# MIMXRT1052 register map
Vendor: nxp.com; File version: 1.0
CPU: CM7 r0p1, little endian, MPU, FPU, VTOR, 4 interrupt priority bits
Registers are 32-bit, read-write, reset 0x0 unless marked. A register's access mark holds for its fields unless they carry their own. Offsets are from the block's base; [hi:lo] are bit positions; {n}, {i} and the like mark numbered series; 'fields as' and 'values as' point back to an identical list.

## FLEXIO1 — FLEXIO
Base 0x401AC000
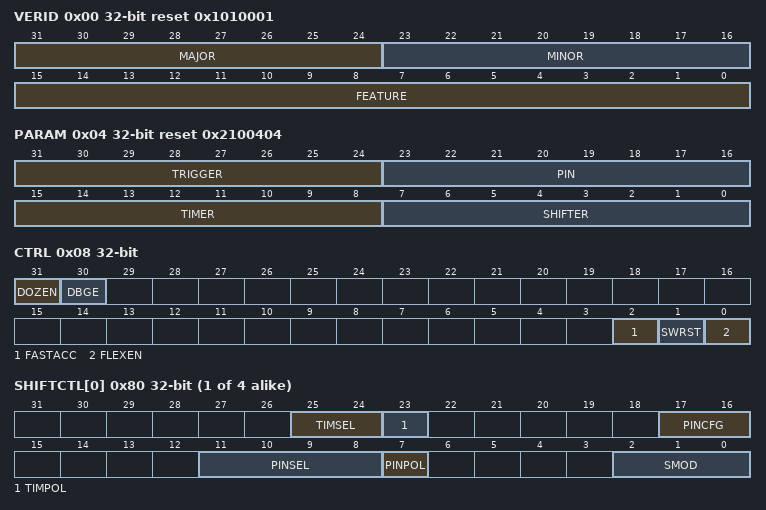
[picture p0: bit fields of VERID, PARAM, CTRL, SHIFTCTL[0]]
0x00 VERID ro reset 0x1010001 — Version ID Register
  [31:24] MAJOR — Major Version Number
  [23:16] MINOR — Minor Version Number
  [15:0] FEATURE — Feature Specification Number
    0=Standard features implemented; 1=Supports state, logic and parallel modes
0x04 PARAM ro reset 0x2100404 — Parameter Register
  [31:24] TRIGGER — Trigger Number
  [23:16] PIN — Pin Number
  [15:8] TIMER — Timer Number
  [7:0] SHIFTER — Shifter Number
0x08 CTRL — FlexIO Control Register
  [31] DOZEN — Doze Enable
    0=FlexIO enabled in Doze modes; 1=FlexIO disabled in Doze modes
  [30] DBGE — Debug Enable
    0=FlexIO is disabled in debug modes; 1=FlexIO is enabled in debug modes
  [2] FASTACC — Fast Access
    0=Configures for normal register accesses to FlexIO; 1=Configures for fast register accesses to FlexIO
  [1] SWRST — Software Reset
    0=Software reset is disabled; 1=Software reset is enabled, all FlexIO registers except the Control Register are reset
  [0] FLEXEN — FlexIO Enable
    0=FlexIO module is disabled; 1=FlexIO module is enabled
0x0C PIN ro — Pin State Register
  [15:0] PDI — Pin Data Input
0x10 SHIFTSTAT — Shifter Status Register
  [3:0] SSF write-1-clears — Shifter Status Flag
0x14 SHIFTERR — Shifter Error Register
  [3:0] SEF write-1-clears — Shifter Error Flags
0x18 TIMSTAT — Timer Status Register
  [3:0] TSF write-1-clears — Timer Status Flags
0x20 SHIFTSIEN — Shifter Status Interrupt Enable
  [3:0] SSIE
0x24 SHIFTEIEN — Shifter Error Interrupt Enable
  [3:0] SEIE
0x28 TIMIEN — Timer Interrupt Enable Register
  [3:0] TEIE — Timer Status Interrupt Enable
0x30 SHIFTSDEN — Shifter Status DMA Enable
  [3:0] SSDE
0x40 SHIFTSTATE — Shifter State Register
  [2:0] STATE — Current State Pointer
{0x80+4i} SHIFTCTL[{i}] (i=0..3) — Shifter Control N Register
  [25:24] TIMSEL — Timer Select
  [23] TIMPOL — Timer Polarity
    0=Shift on posedge of Shift clock; 1=Shift on negedge of Shift clock
  [17:16] PINCFG — Shifter Pin Configuration
    0=Shifter pin output disabled; 1=Shifter pin open drain or bidirectional output enable; 2=Shifter pin bidirectional output data; 3=Shifter pin output
  [11:8] PINSEL — Shifter Pin Select
  [7] PINPOL — Shifter Pin Polarity
    0=Pin is active high; 1=Pin is active low
  [2:0] SMOD — Shifter Mode
    0=Disabled; 1=Receive mode. Captures the current Shifter content into the SHIFTBUF on expiration of the Timer.; 2=Transmit mode. Load SHIFTBUF contents into the Shifter on expiration of the Timer.; 4=Match Store mode. Shifter data is compared to SHIFTBUF content on expiration of the Timer.; 5=Match Continuous mode. Shifter data is continuously compared to SHIFTBUF contents.; 6=State mode. SHIFTBUF contents are used for storing programmable state attributes.; 7=Logic mode. SHIFTBUF contents are used for implementing programmable logic look up table.
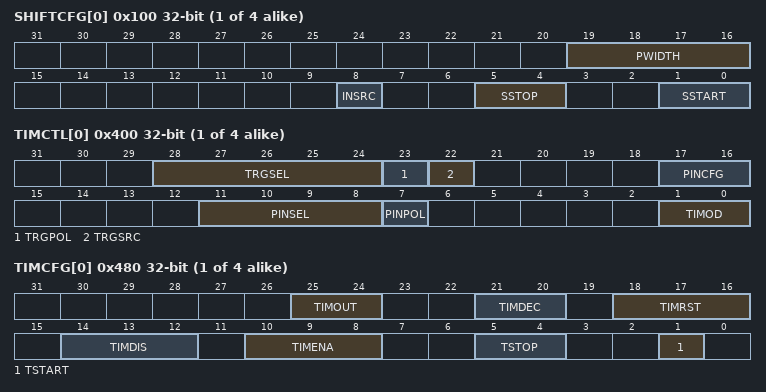
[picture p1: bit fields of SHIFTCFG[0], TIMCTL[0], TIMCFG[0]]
{0x100+4i} SHIFTCFG[{i}] (i=0..3) — Shifter Configuration N Register
  [19:16] PWIDTH — Parallel Width
  [8] INSRC — Input Source
    0=Pin; 1=Shifter N+1 Output
  [5:4] SSTOP — Shifter Stop bit
    0=Stop bit disabled for transmitter/receiver/match store; 2=Transmitter outputs stop bit value 0 on store, receiver/match store sets error flag if stop bit is not 0; 3=Transmitter outputs stop bit value 1 on store, receiver/match store sets error flag if stop bit is not 1
  [1:0] SSTART — Shifter Start bit
    0=Start bit disabled for transmitter/receiver/match store, transmitter loads data on enable; 1=Start bit disabled for transmitter/receiver/match store, transmitter loads data on first shift; 2=Transmitter outputs start bit value 0 before loading data on first shift, receiver/match store sets error flag if start bit is not 0; 3=Transmitter outputs start bit value 1 before loading data on first shift, receiver/match store sets error flag if start bit is not 1
{0x200+4i} SHIFTBUF[{i}] (i=0..3) — Shifter Buffer N Register
  [31:0] SHIFTBUF — Shift Buffer
{0x280+4i} SHIFTBUFBIS[{i}] (i=0..3) — Shifter Buffer N Bit Swapped Register
  [31:0] SHIFTBUFBIS — Shift Buffer
{0x300+4i} SHIFTBUFBYS[{i}] (i=0..3) — Shifter Buffer N Byte Swapped Register
  [31:0] SHIFTBUFBYS — Shift Buffer
{0x380+4i} SHIFTBUFBBS[{i}] (i=0..3) — Shifter Buffer N Bit Byte Swapped Register
  [31:0] SHIFTBUFBBS — Shift Buffer
{0x400+4i} TIMCTL[{i}] (i=0..3) — Timer Control N Register
  [28:24] TRGSEL — Trigger Select
  [23] TRGPOL — Trigger Polarity
    0=Trigger active high; 1=Trigger active low
  [22] TRGSRC — Trigger Source
    0=External trigger selected; 1=Internal trigger selected
  [17:16] PINCFG — Timer Pin Configuration
    0=Timer pin output disabled; 1=Timer pin open drain or bidirectional output enable; 2=Timer pin bidirectional output data; 3=Timer pin output
  [11:8] PINSEL — Timer Pin Select
  [7] PINPOL — Timer Pin Polarity
    0=Pin is active high; 1=Pin is active low
  [1:0] TIMOD — Timer Mode
    0=Timer Disabled; 1=Dual 8-bit counters baud mode; 2=Dual 8-bit counters PWM high mode; 3=Single 16-bit counter mode
{0x480+4i} TIMCFG[{i}] (i=0..3) — Timer Configuration N Register
  [25:24] TIMOUT — Timer Output
    0=Timer output is logic one when enabled and is not affected by timer reset; 1=Timer output is logic zero when enabled and is not affected by timer reset; 2=Timer output is logic one when enabled and on timer reset; 3=Timer output is logic zero when enabled and on timer reset
  [21:20] TIMDEC — Timer Decrement
    0=Decrement counter on FlexIO clock, Shift clock equals Timer output; 1=Decrement counter on Trigger input (both edges), Shift clock equals Timer output; 2=Decrement counter on Pin input (both edges), Shift clock equals Pin input; 3=Decrement counter on Trigger input (both edges), Shift clock equals Trigger input
  [18:16] TIMRST — Timer Reset
    0=Timer never reset; 2=Timer reset on Timer Pin equal to Timer Output; 3=Timer reset on Timer Trigger equal to Timer Output; 4=Timer reset on Timer Pin rising edge; 6=Timer reset on Trigger rising edge; 7=Timer reset on Trigger rising or falling edge
  [14:12] TIMDIS — Timer Disable
    0=Timer never disabled; 1=Timer disabled on Timer N-1 disable; 2=Timer disabled on Timer compare (upper 8-bits match and decrement); 3=Timer disabled on Timer compare (upper 8-bits match and decrement) and Trigger Low; 4=Timer disabled on Pin rising or falling edge; 5=Timer disabled on Pin rising or falling edge provided Trigger is high; 6=Timer disabled on Trigger falling edge
  [10:8] TIMENA — Timer Enable
    0=Timer always enabled; 1=Timer enabled on Timer N-1 enable; 2=Timer enabled on Trigger high; 3=Timer enabled on Trigger high and Pin high; 4=Timer enabled on Pin rising edge; 5=Timer enabled on Pin rising edge and Trigger high; 6=Timer enabled on Trigger rising edge; 7=Timer enabled on Trigger rising or falling edge
  [5:4] TSTOP — Timer Stop Bit
    0=Stop bit disabled; 1=Stop bit is enabled on timer compare; 2=Stop bit is enabled on timer disable; 3=Stop bit is enabled on timer compare and timer disable
  [1] TSTART — Timer Start Bit
    0=Start bit disabled; 1=Start bit enabled
{0x500+4i} TIMCMP[{i}] (i=0..3) — Timer Compare N Register
  [15:0] CMP — Timer Compare Value
{0x680+4i} SHIFTBUFNBS[{i}] (i=0..3) — Shifter Buffer N Nibble Byte Swapped Register
  [31:0] SHIFTBUFNBS — Shift Buffer
{0x700+4i} SHIFTBUFHWS[{i}] (i=0..3) — Shifter Buffer N Half Word Swapped Register
  [31:0] SHIFTBUFHWS — Shift Buffer
{0x780+4i} SHIFTBUFNIS[{i}] (i=0..3) — Shifter Buffer N Nibble Swapped Register
  [31:0] SHIFTBUFNIS — Shift Buffer

## FLEXIO2 — FLEXIO
Base 0x401B0000
Registers as FLEXIO1; these are added or differ:
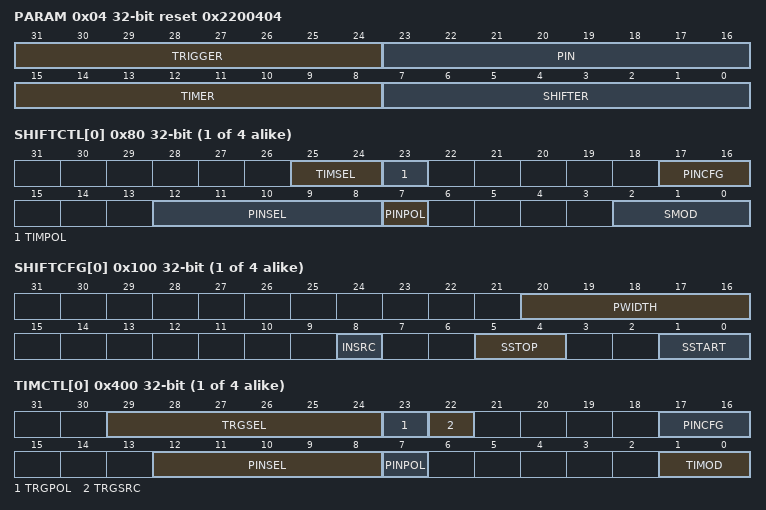
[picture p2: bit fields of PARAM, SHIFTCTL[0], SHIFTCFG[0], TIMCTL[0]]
0x04 PARAM ro reset 0x2200404 — Parameter Register
  [31:24] TRIGGER — Trigger Number
  [23:16] PIN — Pin Number
  [15:8] TIMER — Timer Number
  [7:0] SHIFTER — Shifter Number
0x0C PIN ro — Pin State Register
  [31:0] PDI — Pin Data Input
{0x80+4i} SHIFTCTL[{i}] (i=0..3) — Shifter Control N Register
  [25:24] TIMSEL — Timer Select
  [23] TIMPOL — Timer Polarity
    0=Shift on posedge of Shift clock; 1=Shift on negedge of Shift clock
  [17:16] PINCFG — Shifter Pin Configuration
    0=Shifter pin output disabled; 1=Shifter pin open drain or bidirectional output enable; 2=Shifter pin bidirectional output data; 3=Shifter pin output
  [12:8] PINSEL — Shifter Pin Select
  [7] PINPOL — Shifter Pin Polarity
    0=Pin is active high; 1=Pin is active low
  [2:0] SMOD — Shifter Mode
    values as FLEXIO1.SHIFTCTL[0].SMOD
{0x100+4i} SHIFTCFG[{i}] (i=0..3) — Shifter Configuration N Register
  [20:16] PWIDTH — Parallel Width
  [8] INSRC — Input Source
    0=Pin; 1=Shifter N+1 Output
  [5:4] SSTOP — Shifter Stop bit
    values as FLEXIO1.SHIFTCFG[0].SSTOP
  [1:0] SSTART — Shifter Start bit
    values as FLEXIO1.SHIFTCFG[0].SSTART
{0x400+4i} TIMCTL[{i}] (i=0..3) — Timer Control N Register
  [29:24] TRGSEL — Trigger Select
  [23] TRGPOL — Trigger Polarity
    0=Trigger active high; 1=Trigger active low
  [22] TRGSRC — Trigger Source
    0=External trigger selected; 1=Internal trigger selected
  [17:16] PINCFG — Timer Pin Configuration
    0=Timer pin output disabled; 1=Timer pin open drain or bidirectional output enable; 2=Timer pin bidirectional output data; 3=Timer pin output
  [12:8] PINSEL — Timer Pin Select
  [7] PINPOL — Timer Pin Polarity
    0=Pin is active high; 1=Pin is active low
  [1:0] TIMOD — Timer Mode
    0=Timer Disabled; 1=Dual 8-bit counters baud mode; 2=Dual 8-bit counters PWM high mode; 3=Single 16-bit counter mode
